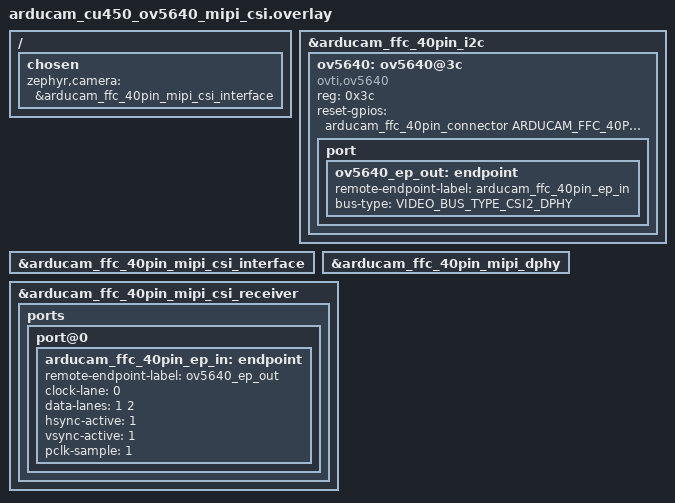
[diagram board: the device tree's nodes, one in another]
/*
 * Copyright (c) 2026 Renesas Electronics Corporation
 *
 * SPDX-License-Identifier: Apache-2.0
 */

#include <zephyr/dt-bindings/video/video-interfaces.h>

/ {
	chosen {
		zephyr,camera = &arducam_ffc_40pin_mipi_csi_interface;
	};
};

&arducam_ffc_40pin_i2c {
	status = "okay";

	ov5640: ov5640@3c {
		compatible = "ovti,ov5640";
		reg = <0x3c>;
		reset-gpios = <&arducam_ffc_40pin_connector
			       ARDUCAM_FFC_40PIN_RESET
			       GPIO_ACTIVE_LOW>;
		status = "okay";

		port {
			ov5640_ep_out: endpoint {
				remote-endpoint-label = "arducam_ffc_40pin_ep_in";
				bus-type = <VIDEO_BUS_TYPE_CSI2_DPHY>;
			};
		};
	};
};

&arducam_ffc_40pin_mipi_csi_interface {
	status = "okay";
};

&arducam_ffc_40pin_mipi_dphy {
	status = "okay";
};

&arducam_ffc_40pin_mipi_csi_receiver {
	status = "okay";

	ports {
		port@0 {
			arducam_ffc_40pin_ep_in: endpoint {
				remote-endpoint-label = "ov5640_ep_out";
				clock-lane = <0>;
				data-lanes = <1 2>;
				hsync-active = <1>;
				vsync-active = <1>;
				pclk-sample = <1>;
			};
		};
	};
};
